# DA14580 register map
Vendor: Dialog; Series: DA14580x; File version: 1.2
CPU: CM0 r1p0, little endian, MPU, FPU, 3 interrupt priority bits
Registers are 16-bit, read-write, reset 0x0 unless marked. A register's access mark holds for its fields unless they carry their own. Offsets are from the block's base; [hi:lo] are bit positions; {n}, {i} and the like mark numbered series; 'fields as' and 'values as' point back to an identical list.

## gpio580_ports_nl01 — gpio580_ports_nl01 registers
Base 0x50003000
0x00 P0_DATA_REG — P0 Data input / output register
  [7:0] P0_DATA — Set P0 output register when written; Returns the value of P0 port when read
0x02 P0_SET_DATA_REG — P0 Set port pins register
  [7:0] P0_SET — Writing a 1 to P0[y] sets P0[y] to 1. Writing 0 is discarded; Reading returns 0
0x04 P0_RESET_DATA_REG — P0 Reset port pins register
  [7:0] P0_RESET — Writing a 1 to P0[y] sets P0[y] to 0. Writing 0 is discarded; Reading returns 0
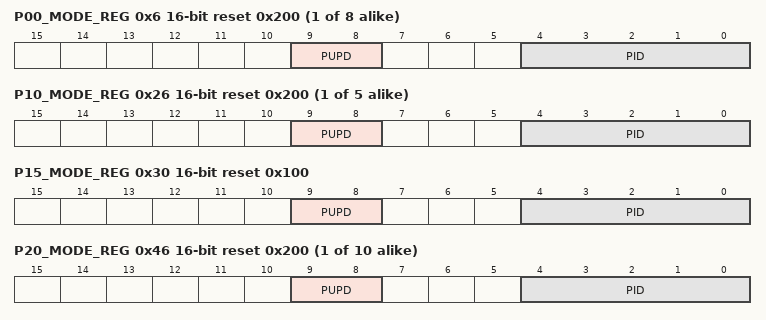
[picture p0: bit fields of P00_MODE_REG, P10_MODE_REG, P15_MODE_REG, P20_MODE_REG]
{0x6+2i} P{i:02}_MODE_REG reset 0x200 (i=0..7) — P{i:02} Mode Register
  [9:8] PUPD — 00 = Input, no resistors selected 01 = Input, pull-up selected 10 = Input, Pull-down selected 11 = Output, no resistors selected In ADC mode, these bits are don't care
  [4:0] PID — Function of port 0 = Port function, PUPD as set above 1 = UART1_RX 2 = UART1_TX 3 = UART2_RX 4 = UART2_TX 5 = SPI_DI 6 = SPI_DO 7 = SPI_CLK 8 = SPI_EN 9 = I2C_SCL 10 = I2C_SDA 11 = UART1_IRDA_RX 12 = UART1_IRDA_TX 13 = UART2_IRDA_RX 14 = UART2_IRDA_TX 15 = ADC (only for P0[3:0]) 16 = PWM0 17 = PWM1 18 = BLE_DIAG (only for P0[7:0]) 19 = UART1_CTSN 20 = UART1_RTSN 21 = UART2_CTSN 22 = UART2_RTSN 23 = PWM2 24 = PWM3 25 = PWM4 Note: when a certain input function (like SPI_DI) is selected on more than 1 port pin, the port with the lowest index has the highest priority and P0 has higher priority than P1.
0x20 P1_DATA_REG — P1 Data input / output register
  [7:0] P1_DATA — Set P1 output register when written; Returns the value of P1 port when read
0x22 P1_SET_DATA_REG — P1 Set port pins register
  [7:0] P1_SET — Writing a 1 to P1[y] sets P1[y] to 1. Writing 0 is discarded; Reading returns 0
0x24 P1_RESET_DATA_REG — P1 Reset port pins register
  [7:0] P1_RESET — Writing a 1 to P1[y] sets P1[y] to 0. Writing 0 is discarded; Reading returns 0
{0x12+2i} P{i}_MODE_REG reset 0x200 (i=10..14) — P{i} Mode Register
  [9:8] PUPD — 00 = Input, no resistors selected 01 = Input, pull-up selected 10 = Input, Pull-down selected 11 = Output, no resistors selected In analog mode, these bits are don't care P14_MODE_REG and P15_MODE_REG reset value is 1 (i.e. pulled up)
  [4:0] PID — See P0x_MODE_REG[PID]
0x30 P15_MODE_REG reset 0x100 — P15 Mode Register
  fields as P10_MODE_REG
0x40 P2_DATA_REG — P2 Data input / output register
  [9:0] P2_DATA — Set P2 output register when written; Returns the value of P2 port when read
0x42 P2_SET_DATA_REG — P2 Set port pins register
  [9:0] P2_SET — Writing a 1 to P2[y] sets P2[y] to 1. Writing 0 is discarded; Reading returns 0
0x44 P2_RESET_DATA_REG — P2 Reset port pins register
  [9:0] P2_RESET — Writing a 1 to P2[y] sets P2[y] to 0. Writing 0 is discarded; Reading returns 0
{0x1E+2i} P{i}_MODE_REG reset 0x200 (i=20..29) — P{i} Mode Register
  [9:8] PUPD — 00 = Input, no resistors selected 01 = Input, pull-up selected 10 = Input, Pull-down selected 11 = Output, no resistors selected In analog mode, these bits are don't care
  [4:0] PID — See P0x_MODE_REG[PID]
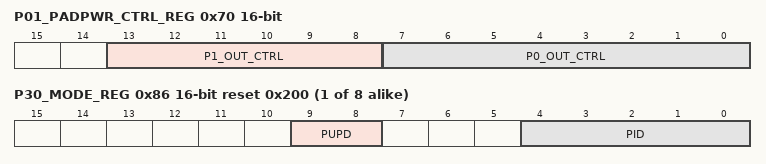
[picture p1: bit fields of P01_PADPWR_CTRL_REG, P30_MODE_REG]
0x70 P01_PADPWR_CTRL_REG — Ports 0 and 1 Output Power Control Register
  [13:8] P1_OUT_CTRL — 1 = P1_x port output is powered by the 1 V rail 0 = P1_x port output is powered by the 3 V rail bit 8 controls the power of P1[0], bit 13 controls the power of P1[5]
  [7:0] P0_OUT_CTRL — 1 = P0_x port output is powered by the 1 V rail 0 = P0_x port output is powered by the 3 V rail bit 0 controls the power of P0[0], bit 7 controls the power of P0[7]
0x72 P2_PADPWR_CTRL_REG — Port 2 Output Power Control Register
  [9:0] P2_OUT_CTRL — 1 = P2_x port output is powered by the 1 V rail 0 = P2_x port output is powered by the 3 V rail bit 0 controls the power of P2[0], bit 9 controls the power of P2[9],
0x74 P3_PADPWR_CTRL_REG — Port 3 Output Power Control Register
  [7:0] P3_OUT_CTRL — 1 = P3_x port output is powered by the 1 V rail 0 = P3_x port output is powered by the 3 V rail bit 0 controls the power of P3[0], bit 7 controls the power of P3[7],
0x80 P3_DATA_REG — P3 Data input / output register
  [7:0] P3_DATA — Set P3 output register when written; Returns the value of P3 port when read
0x82 P3_SET_DATA_REG — P3 Set port pins register
  [7:0] P3_SET wo — Writing a 1 to P3[y] sets P3[y] to 1. Writing 0 is discarded; Reading returns 0
0x84 P3_RESET_DATA_REG — P3 Reset port pins register
  [7:0] P3_RESET wo — Writing a 1 to P0[y] sets P0[y] to 0. Writing 0 is discarded; Reading returns 0
{0x4A+2i} P{i}_MODE_REG reset 0x200 (i=30..37) — P{i} Mode Register
  [9:8] PUPD — 00 = Input, no resistors selected 01 = Input, pull-up selected 10 = Input, Pull-down selected 11 = Output, no resistors selected In ADC mode, these bits are don't care
  [4:0] PID — See P0x_MODE_REG[PID]
